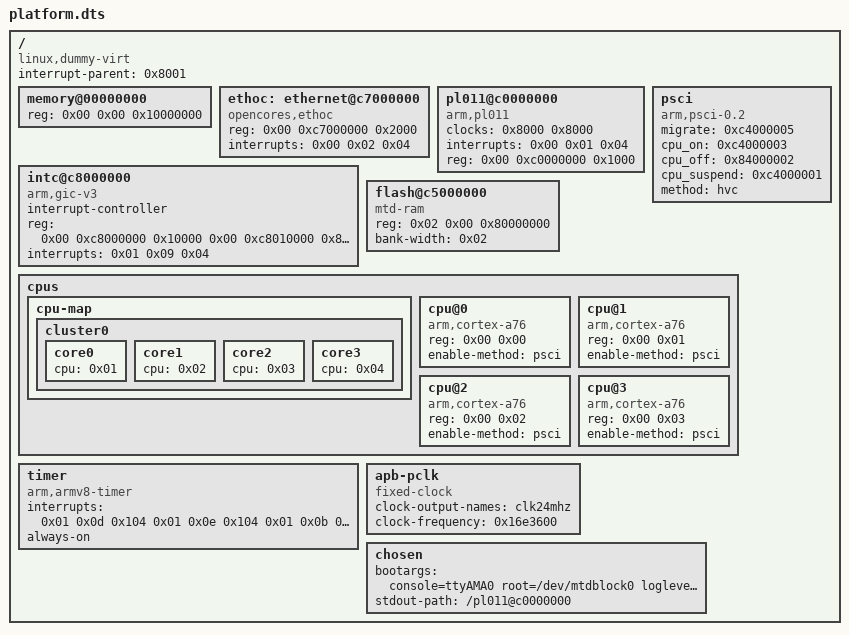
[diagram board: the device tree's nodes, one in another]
/dts-v1/;

/ {
	interrupt-parent = <0x8001>;
	#size-cells = <0x01>;
	#address-cells = <0x02>;
	compatible = "linux,dummy-virt";

	memory@00000000 {
		reg = <0x00 0x00 0x10000000>;
		device_type = "memory";
	};

	ethoc: ethernet@c7000000 {
		compatible = "opencores,ethoc";
		reg = <0x00 0xc7000000 0x2000>;
		interrupts = <0x00 0x02 0x04>;
	};

	pl011@c0000000 {
		clock-names = "uartclk\0apb_pclk";
		clocks = <0x8000 0x8000>;
		interrupts = <0x00 0x01 0x04>;
		reg = <0x00 0xc0000000 0x1000>;
		compatible = "arm,pl011\0arm,primecell";
	};

	intc@c8000000 {
		compatible = "arm,gic-v3";
		#interrupt-cells = <0x03>;
		#address-cells = <0x02>;
		#size-cells = <0x02>;
		ranges;
		interrupt-controller;
		phandle = <0x8001>;
		reg = <0x00 0xc8000000 0x10000 0x00 0xc8010000 0x800000>;
		interrupts = <0x01 0x09 0x04>;
	};

	psci {
		migrate = <0xc4000005>;
		cpu_on = <0xc4000003>;
		cpu_off = <0x84000002>;
		cpu_suspend = <0xc4000001>;
		method = "hvc";
		compatible = "arm,psci-0.2\0arm,psci";
	};

    flash@c5000000 {
        compatible = "mtd-ram";
        reg = <0x02 0x00 0x80000000>;
        bank-width = <0x02>;
    };

	cpus {
		#size-cells = <0x00>;
		#address-cells = <0x02>;

		cpu-map {
			cluster0 {
				core0 {
					cpu = <0x01>;
				};

				core1 {
					cpu = <0x02>;
				};

				core2 {
					cpu = <0x03>;
				};

				core3 {
					cpu = <0x04>;
				};
			};

        };

		cpu@0 {
			device_type = "cpu";
			compatible = "arm,cortex-a76";
			reg = <0x00 0x00>;
			enable-method = "psci";
			phandle = <0x01>;
		};

		cpu@1 {
			device_type = "cpu";
			compatible = "arm,cortex-a76";
			reg = <0x00 0x01>;
			enable-method = "psci";
			phandle = <0x02>;
		};

		cpu@2 {
			device_type = "cpu";
			compatible = "arm,cortex-a76";
			reg = <0x00 0x02>;
			enable-method = "psci";
			phandle = <0x03>;
		};

		cpu@3 {
			device_type = "cpu";
			compatible = "arm,cortex-a76";
			reg = <0x00 0x03>;
			enable-method = "psci";
			phandle = <0x04>;
		};
	};

	timer {
		interrupts = <0x01 0x0d 0x104 0x01 0x0e 0x104 0x01 0x0b 0x104 0x01 0x0a 0x104>;
		always-on;
		compatible = "arm,armv8-timer\0arm,armv7-timer";
	};

	apb-pclk {
		phandle = <0x8000>;
		clock-output-names = "clk24mhz";
		clock-frequency = <0x16e3600>;
		#clock-cells = <0x00>;
		compatible = "fixed-clock";
	};

	chosen {
		bootargs = "console=ttyAMA0 root=/dev/mtdblock0 loglevel=8 earlyprintk earlycon";
		stdout-path = "/pl011@c0000000";
	};
};
